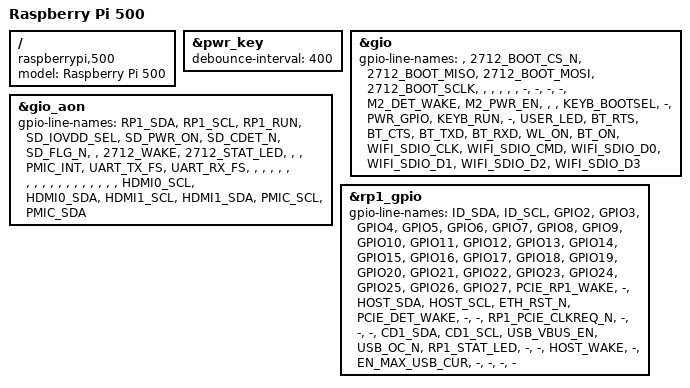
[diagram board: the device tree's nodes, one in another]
// SPDX-License-Identifier: GPL-2.0
#include "bcm2712d0-rpi-5-b.dts"

/ {
	compatible = "raspberrypi,500", "brcm,bcm2712";
	model = "Raspberry Pi 500";
};

&pwr_key {
	debounce-interval = <400>;
};

&gio {
	gpio-line-names =
		"", // GPIO_000
		"2712_BOOT_CS_N", // GPIO_001
		"2712_BOOT_MISO", // GPIO_002
		"2712_BOOT_MOSI", // GPIO_003
		"2712_BOOT_SCLK", // GPIO_004
		"", // GPIO_005
		"", // GPIO_006
		"", // GPIO_007
		"", // GPIO_008
		"", // GPIO_009
		"-", // GPIO_010
		"-", // GPIO_011
		"-", // GPIO_012
		"-", // GPIO_013
		"M2_DET_WAKE", // GPIO_014
		"M2_PWR_EN", // GPIO_015
		"", // GPIO_016
		"", // GPIO_017
		"KEYB_BOOTSEL", // GPIO_018
		"-", // GPIO_019
		"PWR_GPIO", // GPIO_020
		"KEYB_RUN", // GPIO_021
		"-", // GPIO_022
		"USER_LED", // GPIO_023
		"BT_RTS", // GPIO_024
		"BT_CTS", // GPIO_025
		"BT_TXD", // GPIO_026
		"BT_RXD", // GPIO_027
		"WL_ON", // GPIO_028
		"BT_ON", // GPIO_029
		"WIFI_SDIO_CLK", // GPIO_030
		"WIFI_SDIO_CMD", // GPIO_031
		"WIFI_SDIO_D0", // GPIO_032
		"WIFI_SDIO_D1", // GPIO_033
		"WIFI_SDIO_D2", // GPIO_034
		"WIFI_SDIO_D3"; // GPIO_035
};

&gio_aon {
	gpio-line-names =
		"RP1_SDA", // AON_GPIO_00
		"RP1_SCL", // AON_GPIO_01
		"RP1_RUN", // AON_GPIO_02
		"SD_IOVDD_SEL", // AON_GPIO_03
		"SD_PWR_ON", // AON_GPIO_04
		"SD_CDET_N", // AON_GPIO_05
		"SD_FLG_N", // AON_GPIO_06
		"", // AON_GPIO_07
		"2712_WAKE", // AON_GPIO_08
		"2712_STAT_LED", // AON_GPIO_09
		"", // AON_GPIO_10
		"", // AON_GPIO_11
		"PMIC_INT", // AON_GPIO_12
		"UART_TX_FS", // AON_GPIO_13
		"UART_RX_FS", // AON_GPIO_14
		"", // AON_GPIO_15
		"", // AON_GPIO_16

		// Pad bank0 out to 32 entries
		"", "", "", "", "", "", "", "", "", "", "", "", "", "", "",

		"HDMI0_SCL", // AON_SGPIO_00
		"HDMI0_SDA", // AON_SGPIO_01
		"HDMI1_SCL", // AON_SGPIO_02
		"HDMI1_SDA", // AON_SGPIO_03
		"PMIC_SCL", // AON_SGPIO_04
		"PMIC_SDA"; // AON_SGPIO_05
};

&rp1_gpio {
	gpio-line-names =
		"ID_SDA", // GPIO0
		"ID_SCL", // GPIO1
		"GPIO2", // GPIO2
		"GPIO3", // GPIO3
		"GPIO4", // GPIO4
		"GPIO5", // GPIO5
		"GPIO6", // GPIO6
		"GPIO7", // GPIO7
		"GPIO8", // GPIO8
		"GPIO9", // GPIO9
		"GPIO10", // GPIO10
		"GPIO11", // GPIO11
		"GPIO12", // GPIO12
		"GPIO13", // GPIO13
		"GPIO14", // GPIO14
		"GPIO15", // GPIO15
		"GPIO16", // GPIO16
		"GPIO17", // GPIO17
		"GPIO18", // GPIO18
		"GPIO19", // GPIO19
		"GPIO20", // GPIO20
		"GPIO21", // GPIO21
		"GPIO22", // GPIO22
		"GPIO23", // GPIO23
		"GPIO24", // GPIO24
		"GPIO25", // GPIO25
		"GPIO26", // GPIO26
		"GPIO27", // GPIO27

		"PCIE_RP1_WAKE", // GPIO28
		"-", // GPIO29
		"HOST_SDA", // GPIO30
		"HOST_SCL", // GPIO31
		"ETH_RST_N", // GPIO32
		"PCIE_DET_WAKE", // GPIO33

		"-", // GPIO34
		"-", // GPIO35
		"RP1_PCIE_CLKREQ_N", // GPIO36
		"-", // GPIO37
		"-", // GPIO38
		"-", // GPIO39
		"CD1_SDA", // GPIO40
		"CD1_SCL", // GPIO41
		"USB_VBUS_EN", // GPIO42
		"USB_OC_N", // GPIO43
		"RP1_STAT_LED", // GPIO44
		"-", // GPIO45
		"-", // GPIO46
		"HOST_WAKE", // GPIO47
		"-", // GPIO48
		"EN_MAX_USB_CUR", // GPIO49
		"-", // GPIO50
		"-", // GPIO51
		"-", // GPIO52
		"-"; // GPIO53
};
